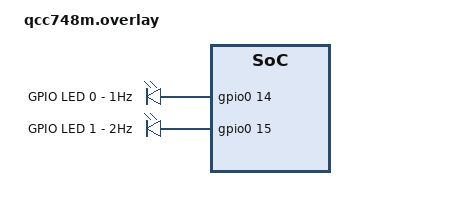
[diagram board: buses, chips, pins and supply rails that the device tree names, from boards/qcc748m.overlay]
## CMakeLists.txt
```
# SPDX-License-Identifier: Apache-2.0

cmake_minimum_required(VERSION 3.20.0)

# Try to find Zephyr, but don't fail if not found
find_package(Zephyr QUIET HINTS $ENV{ZEPHYR_BASE})

if(Zephyr_FOUND)
    project(zephyr_gpio_blinky)
    target_sources(app PRIVATE src/main.c)
else()
    message(WARNING "Zephyr SDK not found - this is a Zephyr RTOS project")
    message(STATUS "Install Zephyr: https://docs.zephyrproject.org/latest/getting_started/")
    project(zephyr_gpio_blinky NONE)
endif()
```

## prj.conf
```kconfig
# Enable GPIO driver
CONFIG_GPIO=y

# Enable console/UART for logging
CONFIG_CONSOLE=y
CONFIG_UART_CONSOLE=y
CONFIG_SERIAL=y

# Enable printk for debugging
CONFIG_PRINTK=y

# Kernel configuration
CONFIG_MAIN_STACK_SIZE=2048
CONFIG_SYSTEM_WORKQUEUE_STACK_SIZE=2048

# Enable multithreading (enabled by default, but explicit for clarity)
CONFIG_MULTITHREADING=y

# Optional: Enable kernel object debug
CONFIG_THREAD_NAME=y
CONFIG_THREAD_MONITOR=y
```

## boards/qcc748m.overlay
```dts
/*
 * Copyright (c) 2024 Qualcomm Innovation Center, Inc.
 *
 * SPDX-License-Identifier: Apache-2.0
 */

/ {
	aliases {
		led0 = &gpio_led0;
		led1 = &gpio_led1;
	};

	gpio_leds {
		compatible = "gpio-leds";

		gpio_led0: gpio_led_0 {
			/* GPIO14 - Channel 1 for logic analyzer */
			gpios = <&gpio0 14 GPIO_ACTIVE_HIGH>;
			label = "GPIO LED 0 - 1Hz";
		};

		gpio_led1: gpio_led_1 {
			/* GPIO15 - Channel 2 for logic analyzer */
			gpios = <&gpio0 15 GPIO_ACTIVE_HIGH>;
			label = "GPIO LED 1 - 2Hz";
		};
	};
};
```

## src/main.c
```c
/*
 * Copyright (c) 2024 Qualcomm Innovation Center, Inc.
 *
 * SPDX-License-Identifier: Apache-2.0
 */

#include <zephyr/kernel.h>
#include <zephyr/drivers/gpio.h>
#include <zephyr/sys/printk.h>

/* Thread stack sizes */
#define STACKSIZE 1024

/* Thread priorities */
#define THREAD0_PRIORITY 7
#define THREAD1_PRIORITY 7

/* GPIO specifications from device tree */
#define LED0_NODE DT_ALIAS(led0)
#define LED1_NODE DT_ALIAS(led1)

#if !DT_NODE_HAS_STATUS(LED0_NODE, okay)
#error "Unsupported board: led0 devicetree alias is not defined or enabled"
#endif

#if !DT_NODE_HAS_STATUS(LED1_NODE, okay)
#error "Unsupported board: led1 devicetree alias is not defined or enabled"
#endif

static const struct gpio_dt_spec led0 = GPIO_DT_SPEC_GET(LED0_NODE, gpios);
static const struct gpio_dt_spec led1 = GPIO_DT_SPEC_GET(LED1_NODE, gpios);

/* Thread 0: Toggle LED0/GPIO at 1Hz */
void thread0_entry(void *p1, void *p2, void *p3)
{
	ARG_UNUSED(p1);
	ARG_UNUSED(p2);
	ARG_UNUSED(p3);

	int ret;

	printk("Thread 0 started - GPIO %d (LED0) toggling at 1Hz\n", led0.pin);

	ret = gpio_pin_configure_dt(&led0, GPIO_OUTPUT_ACTIVE);
	if (ret < 0) {
		printk("Error %d: failed to configure LED0 pin %d\n", ret, led0.pin);
		return;
	}

	while (1) {
		gpio_pin_toggle_dt(&led0);
		k_msleep(500);  /* Toggle every 500ms = 1Hz square wave */
	}
}

/* Thread 1: Toggle LED1/GPIO at 2Hz */
void thread1_entry(void *p1, void *p2, void *p3)
{
	ARG_UNUSED(p1);
	ARG_UNUSED(p2);
	ARG_UNUSED(p3);

	int ret;

	printk("Thread 1 started - GPIO %d (LED1) toggling at 2Hz\n", led1.pin);

	ret = gpio_pin_configure_dt(&led1, GPIO_OUTPUT_ACTIVE);
	if (ret < 0) {
		printk("Error %d: failed to configure LED1 pin %d\n", ret, led1.pin);
		return;
	}

	while (1) {
		gpio_pin_toggle_dt(&led1);
		k_msleep(250);  /* Toggle every 250ms = 2Hz square wave */
	}
}

/* Define and initialize threads */
K_THREAD_DEFINE(thread0_id, STACKSIZE, thread0_entry, NULL, NULL, NULL,
		THREAD0_PRIORITY, 0, 0);

K_THREAD_DEFINE(thread1_id, STACKSIZE, thread1_entry, NULL, NULL, NULL,
		THREAD1_PRIORITY, 0, 0);

int main(void)
{
	printk("\n");
	printk("╔════════════════════════════════════════╗\n");
	printk("║  Zephyr RTOS Dual-Thread GPIO Blinky  ║\n");
	printk("║  EVK-QCC748M-2-01-0-AA                 ║\n");
	printk("╚════════════════════════════════════════╝\n");
	printk("\n");

	if (!gpio_is_ready_dt(&led0)) {
		printk("Error: LED0 device %s is not ready\n", led0.port->name);
		return 0;
	}

	if (!gpio_is_ready_dt(&led1)) {
		printk("Error: LED1 device %s is not ready\n", led1.port->name);
		return 0;
	}

	printk("GPIO devices ready\n");
	printk("LED0: GPIO %d - 1Hz (500ms period)\n", led0.pin);
	printk("LED1: GPIO %d - 2Hz (250ms period)\n", led1.pin);
	printk("\n");
	printk("Connect logic analyzer to observe:\n");
	printk("  Channel 1: GPIO %d (1Hz square wave)\n", led0.pin);
	printk("  Channel 2: GPIO %d (2Hz square wave)\n", led1.pin);
	printk("\n");

	/* Threads are auto-started by K_THREAD_DEFINE */
	printk("Threads started. Press Ctrl+] to exit monitor.\n");

	return 0;
}
```
